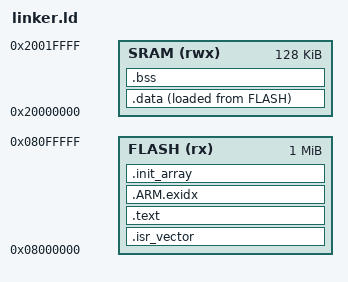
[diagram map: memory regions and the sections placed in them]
ENTRY(Reset_Handler)

MEMORY
{
    FLASH(rx):ORIGIN =0x08000000,LENGTH =1024K
    SRAM(rwx):ORIGIN =0x20000000,LENGTH =128K
}

SECTIONS
{
    .isr_vector :
    {
        . = ALIGN(4);
        KEEP(*(.isr_vector))
        . = ALIGN(4);
    }> FLASH
    .text :
    {
        *(.text)
        *(.text.*)
        *(.init)
        *(.fini)
        *(.rodata)
        *(.rodata.*)
        . = ALIGN(4);
        _etext = .;
    }> FLASH

    __exidx_start = .;
    .ARM.exidx :
    {
        *(.ARM.exidx* .gnu.linkonce.armexidx.*)
    } >FLASH
    __exidx_end = .;

    .init_array :
    {
        . = ALIGN(4);
        PROVIDE_HIDDEN (__preinit_array_start = .);
        KEEP(*(.preinit_array))   /* Pre-initializers */
        PROVIDE_HIDDEN (__preinit_array_end = .);

        . = ALIGN(4);
        PROVIDE_HIDDEN (__init_array_start = .);
        KEEP(*(SORT(.init_array.*))) /* Initializers */
        KEEP(*(.init_array))
        PROVIDE_HIDDEN (__init_array_end = .);

        . = ALIGN(4);
        PROVIDE_HIDDEN (__fini_array_start = .);
        KEEP(*(.fini_array))   /* Destructors */
        PROVIDE_HIDDEN (__fini_array_end = .);
    } > FLASH

    _la_data = LOADADDR(.data);

    .data :
    {
        _sdata = .;
        *(.data)
        *(.data.*)
        . = ALIGN(4);
        _edata = .;
    }> SRAM AT> FLASH

    .bss :
    {
        _sbss = .;
        __bss_start__ = _sbss;
        *(.bss)
        *(.bss.*)
        . = ALIGN(4);
        _ebss = .;
        __bss_end__ = _ebss;
        end = .;
        __end__ = end;
    }> SRAM
}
